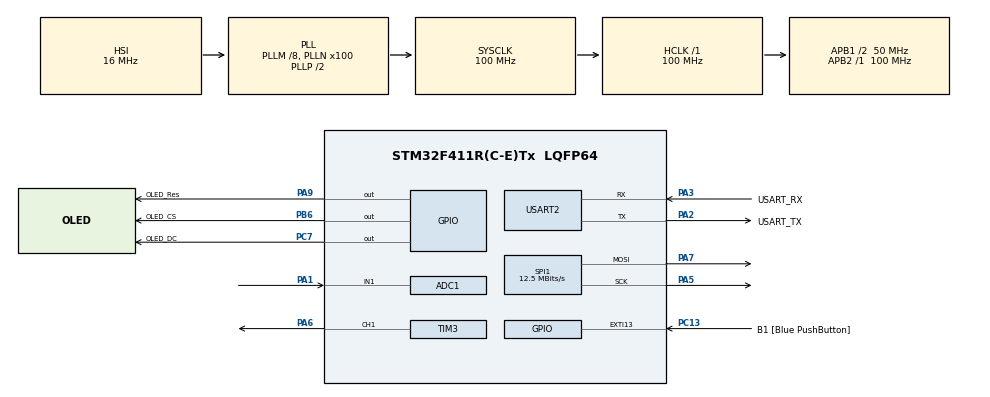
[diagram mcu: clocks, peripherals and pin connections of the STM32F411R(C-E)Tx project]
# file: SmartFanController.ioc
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ADC1.Channel-0\#ChannelRegularConversion=ADC_CHANNEL_1
ADC1.ContinuousConvMode=ENABLE
ADC1.DMAContinuousRequests=ENABLE
ADC1.NbrOfConversionFlag=1
ADC1.Rank-0\#ChannelRegularConversion=1
ADC1.SamplingTime-0\#ChannelRegularConversion=ADC_SAMPLETIME_480CYCLES
ADC1.master=1
Dma.ADC1.0.Direction=DMA_PERIPH_TO_MEMORY
Dma.ADC1.0.FIFOMode=DMA_FIFOMODE_DISABLE
Dma.ADC1.0.Instance=DMA2_Stream0
Dma.ADC1.0.MemDataAlignment=DMA_MDATAALIGN_HALFWORD
Dma.ADC1.0.MemInc=DMA_MINC_ENABLE
Dma.ADC1.0.Mode=DMA_CIRCULAR
Dma.ADC1.0.PeriphDataAlignment=DMA_PDATAALIGN_HALFWORD
Dma.ADC1.0.PeriphInc=DMA_PINC_DISABLE
Dma.ADC1.0.Priority=DMA_PRIORITY_LOW
Dma.Request0=ADC1
Mcu.Family=STM32F4
Mcu.Name=STM32F411R(C-E)Tx
Mcu.Package=LQFP64
NVIC.ADC_IRQn=true\:0\:0\:false\:false\:true\:true\:true\:true
NVIC.DMA2_Stream0_IRQn=true\:0\:0\:false\:false\:true\:false\:true\:true
NVIC.PriorityGroup=NVIC_PRIORITYGROUP_0
NVIC.TIM3_IRQn=true\:0\:0\:false\:false\:true\:true\:true\:true
NVIC.USART2_IRQn=true\:0\:0\:false\:false\:true\:true\:true\:true
PA1.Signal=ADCx_IN1
PA13.GPIO_Label=TMS
PA13.Mode=Serial_Wire
PA13.Signal=SYS_JTMS-SWDIO
PA14.GPIO_Label=TCK
PA14.Mode=Serial_Wire
PA14.Signal=SYS_JTCK-SWCLK
PA2.GPIO_Label=USART_TX
PA2.Mode=Asynchronous
PA2.Signal=USART2_TX
PA3.GPIO_Label=USART_RX
PA3.Mode=Asynchronous
PA3.Signal=USART2_RX
PA5.Mode=TX_Only_Simplex_Unidirect_Master
PA5.Signal=SPI1_SCK
PA6.Signal=S_TIM3_CH1
PA7.Mode=TX_Only_Simplex_Unidirect_Master
PA7.Signal=SPI1_MOSI
PA9.GPIO_Label=OLED_Res
PA9.Signal=GPIO_Output
PB3.GPIO_Label=SWO
PB3.Signal=SYS_JTDO-SWO
PB6.GPIO_Label=OLED_CS
PB6.Signal=GPIO_Output
PC13-ANTI_TAMP.GPIO_Label=B1 [Blue PushButton]
PC13-ANTI_TAMP.GPIO_ModeDefaultEXTI=GPIO_MODE_IT_FALLING
PC13-ANTI_TAMP.Signal=GPXTI13
PC14-OSC32_IN.Mode=LSE-External-Oscillator
PC14-OSC32_IN.Signal=RCC_OSC32_IN
PC15-OSC32_OUT.Mode=LSE-External-Oscillator
PC15-OSC32_OUT.Signal=RCC_OSC32_OUT
PC7.GPIO_Label=OLED_DC
PC7.Signal=GPIO_Output
PH0\ -\ OSC_IN.Mode=HSE-External-Clock-Source
PH0\ -\ OSC_IN.Signal=RCC_OSC_IN
PH1\ -\ OSC_OUT.Mode=HSE-External-Clock-Source
PH1\ -\ OSC_OUT.Signal=RCC_OSC_OUT
ProjectManager.HeapSize=0x200
ProjectManager.StackSize=0x400
ProjectManager.TargetToolchain=STM32CubeIDE
RCC.48MHZClocksFreq_Value=50000000
RCC.AHBFreq_Value=100000000
RCC.APB1CLKDivider=RCC_HCLK_DIV2
RCC.APB1Freq_Value=50000000
RCC.APB1TimFreq_Value=100000000
RCC.APB2Freq_Value=100000000
RCC.APB2TimFreq_Value=100000000
RCC.CortexFreq_Value=100000000
RCC.FLatency-AdvancedSettings=FLASH_LATENCY_3
RCC.HCLKFreq_Value=100000000
RCC.HSE_VALUE=8000000
RCC.HSI_VALUE=16000000
RCC.PLLM=8
RCC.PLLN=100
RCC.SYSCLKFreq_VALUE=100000000
RCC.SYSCLKSource=RCC_SYSCLKSOURCE_PLLCLK
RCC.VCOOutputFreq_Value=200000000
SH.ADCx_IN1.0=ADC1_IN1,IN1
SH.S_TIM3_CH1.0=TIM3_CH1,PWM Generation1 CH1
SPI1.BaudRatePrescaler=SPI_BAUDRATEPRESCALER_8
SPI1.CalculateBaudRate=12.5 MBits/s
SPI1.Direction=SPI_DIRECTION_2LINES
SPI1.Mode=SPI_MODE_MASTER
SPI1.VirtualType=VM_MASTER
TIM3.Channel-PWM\ Generation1\ CH1=TIM_CHANNEL_1
TIM3.Period=1000
TIM3.Prescaler=99
USART2.VirtualMode=VM_ASYNC
VP_TIM3_VS_ClockSourceINT.Mode=Internal
board=NUCLEO-F411RE

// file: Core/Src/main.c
/* USER CODE BEGIN Header */
/**
  ******************************************************************************
  * @file           : main.c
  * @brief          : Main program body
  ******************************************************************************
  * @attention
  *
  * Copyright (c) 2026 STMicroelectronics.
  * All rights reserved.
  *
  * This software is licensed under terms that can be found in the LICENSE file
  * in the root directory of this software component.
  * If no LICENSE file comes with this software, it is provided AS-IS.
  *
  ******************************************************************************
  */
/* USER CODE END Header */
#include "main.h"

/* USER CODE BEGIN Includes */
#include "app.h"
#include "Temp_sensor.h"
#include "UART.h"
#include "ssd1306.h"
/* USER CODE END Includes */

ADC_HandleTypeDef hadc1;
DMA_HandleTypeDef hdma_adc1;

SPI_HandleTypeDef hspi1;

TIM_HandleTypeDef htim3;

UART_HandleTypeDef huart2;

void SystemClock_Config(void);
static void MX_GPIO_Init(void);
static void MX_DMA_Init(void);
static void MX_SPI1_Init(void);
static void MX_TIM3_Init(void);
static void MX_USART2_UART_Init(void);
static void MX_ADC1_Init(void);

int main(void)
{

  /* MCU Configuration--------------------------------------------------------*/

  /* Reset of all peripherals, Initializes the Flash interface and the Systick. */
  HAL_Init();

  /* Configure the system clock */
  SystemClock_Config();

  /* Initialize all configured peripherals */
  MX_GPIO_Init();
  MX_DMA_Init();
  MX_SPI1_Init();
  MX_TIM3_Init();
  MX_USART2_UART_Init();
  MX_ADC1_Init();
  /* USER CODE BEGIN 2 */
  ssd1306_Init();
  HAL_TIM_PWM_Start(&htim3, TIM_CHANNEL_1);
  Temp_init(&hadc1);
  UART_Recive();
  App_Init();
  /* USER CODE END 2 */

  /* Infinite loop */
  /* USER CODE BEGIN WHILE */
  while (1)
  {
	  App_Execution();
	  HAL_Delay(100);
    /* USER CODE END WHILE */

  }
}

void SystemClock_Config(void)
{
  RCC_OscInitTypeDef RCC_OscInitStruct = {0};
  RCC_ClkInitTypeDef RCC_ClkInitStruct = {0};

  /** Configure the main internal regulator output voltage
  */
  __HAL_RCC_PWR_CLK_ENABLE();
  __HAL_PWR_VOLTAGESCALING_CONFIG(PWR_REGULATOR_VOLTAGE_SCALE1);

  /** Initializes the RCC Oscillators according to the specified parameters
  * in the RCC_OscInitTypeDef structure.
  */
  RCC_OscInitStruct.OscillatorType = RCC_OSCILLATORTYPE_HSI;
  RCC_OscInitStruct.HSIState = RCC_HSI_ON;
  RCC_OscInitStruct.HSICalibrationValue = RCC_HSICALIBRATION_DEFAULT;
  RCC_OscInitStruct.PLL.PLLState = RCC_PLL_ON;
  RCC_OscInitStruct.PLL.PLLSource = RCC_PLLSOURCE_HSI;
  RCC_OscInitStruct.PLL.PLLM = 8;
  RCC_OscInitStruct.PLL.PLLN = 100;
  RCC_OscInitStruct.PLL.PLLP = RCC_PLLP_DIV2;
  RCC_OscInitStruct.PLL.PLLQ = 4;
  if (HAL_RCC_OscConfig(&RCC_OscInitStruct) != HAL_OK)
  {
    Error_Handler();
  }

  /** Initializes the CPU, AHB and APB buses clocks
  */
  RCC_ClkInitStruct.ClockType = RCC_CLOCKTYPE_HCLK|RCC_CLOCKTYPE_SYSCLK
                              |RCC_CLOCKTYPE_PCLK1|RCC_CLOCKTYPE_PCLK2;
  RCC_ClkInitStruct.SYSCLKSource = RCC_SYSCLKSOURCE_PLLCLK;
  RCC_ClkInitStruct.AHBCLKDivider = RCC_SYSCLK_DIV1;
  RCC_ClkInitStruct.APB1CLKDivider = RCC_HCLK_DIV2;
  RCC_ClkInitStruct.APB2CLKDivider = RCC_HCLK_DIV1;

  if (HAL_RCC_ClockConfig(&RCC_ClkInitStruct, FLASH_LATENCY_3) != HAL_OK)
  {
    Error_Handler();
  }
}

static void MX_ADC1_Init(void)
{

  ADC_ChannelConfTypeDef sConfig = {0};

  /** Configure the global features of the ADC (Clock, Resolution, Data Alignment and number of conversion)
  */
  hadc1.Instance = ADC1;
  hadc1.Init.ClockPrescaler = ADC_CLOCK_SYNC_PCLK_DIV4;
  hadc1.Init.Resolution = ADC_RESOLUTION_12B;
  hadc1.Init.ScanConvMode = DISABLE;
  hadc1.Init.ContinuousConvMode = ENABLE;
  hadc1.Init.DiscontinuousConvMode = DISABLE;
  hadc1.Init.ExternalTrigConvEdge = ADC_EXTERNALTRIGCONVEDGE_NONE;
  hadc1.Init.ExternalTrigConv = ADC_SOFTWARE_START;
  hadc1.Init.DataAlign = ADC_DATAALIGN_RIGHT;
  hadc1.Init.NbrOfConversion = 1;
  hadc1.Init.DMAContinuousRequests = ENABLE;
  hadc1.Init.EOCSelection = ADC_EOC_SINGLE_CONV;
  if (HAL_ADC_Init(&hadc1) != HAL_OK)
  {
    Error_Handler();
  }

  /** Configure for the selected ADC regular channel its corresponding rank in the sequencer and its sample time.
  */
  sConfig.Channel = ADC_CHANNEL_1;
  sConfig.Rank = 1;
  sConfig.SamplingTime = ADC_SAMPLETIME_480CYCLES;
  if (HAL_ADC_ConfigChannel(&hadc1, &sConfig) != HAL_OK)
  {
    Error_Handler();
  }

}

static void MX_SPI1_Init(void)
{

  /* SPI1 parameter configuration*/
  hspi1.Instance = SPI1;
  hspi1.Init.Mode = SPI_MODE_MASTER;
  hspi1.Init.Direction = SPI_DIRECTION_2LINES;
  hspi1.Init.DataSize = SPI_DATASIZE_8BIT;
  hspi1.Init.CLKPolarity = SPI_POLARITY_LOW;
  hspi1.Init.CLKPhase = SPI_PHASE_1EDGE;
  hspi1.Init.NSS = SPI_NSS_SOFT;
  hspi1.Init.BaudRatePrescaler = SPI_BAUDRATEPRESCALER_8;
  hspi1.Init.FirstBit = SPI_FIRSTBIT_MSB;
  hspi1.Init.TIMode = SPI_TIMODE_DISABLE;
  hspi1.Init.CRCCalculation = SPI_CRCCALCULATION_DISABLE;
  hspi1.Init.CRCPolynomial = 10;
  if (HAL_SPI_Init(&hspi1) != HAL_OK)
  {
    Error_Handler();
  }

}

static void MX_TIM3_Init(void)
{

  TIM_ClockConfigTypeDef sClockSourceConfig = {0};
  TIM_MasterConfigTypeDef sMasterConfig = {0};
  TIM_OC_InitTypeDef sConfigOC = {0};

  htim3.Instance = TIM3;
  htim3.Init.Prescaler = 99;
  htim3.Init.CounterMode = TIM_COUNTERMODE_UP;
  htim3.Init.Period = 1000;
  htim3.Init.ClockDivision = TIM_CLOCKDIVISION_DIV1;
  htim3.Init.AutoReloadPreload = TIM_AUTORELOAD_PRELOAD_DISABLE;
  if (HAL_TIM_Base_Init(&htim3) != HAL_OK)
  {
    Error_Handler();
  }
  sClockSourceConfig.ClockSource = TIM_CLOCKSOURCE_INTERNAL;
  if (HAL_TIM_ConfigClockSource(&htim3, &sClockSourceConfig) != HAL_OK)
  {
    Error_Handler();
  }
  if (HAL_TIM_PWM_Init(&htim3) != HAL_OK)
  {
    Error_Handler();
  }
  sMasterConfig.MasterOutputTrigger = TIM_TRGO_RESET;
  sMasterConfig.MasterSlaveMode = TIM_MASTERSLAVEMODE_DISABLE;
  if (HAL_TIMEx_MasterConfigSynchronization(&htim3, &sMasterConfig) != HAL_OK)
  {
    Error_Handler();
  }
  sConfigOC.OCMode = TIM_OCMODE_PWM1;
  sConfigOC.Pulse = 0;
  sConfigOC.OCPolarity = TIM_OCPOLARITY_HIGH;
  sConfigOC.OCFastMode = TIM_OCFAST_DISABLE;
  if (HAL_TIM_PWM_ConfigChannel(&htim3, &sConfigOC, TIM_CHANNEL_1) != HAL_OK)
  {
    Error_Handler();
  }
  HAL_TIM_MspPostInit(&htim3);

}

static void MX_USART2_UART_Init(void)
{

  huart2.Instance = USART2;
  huart2.Init.BaudRate = 115200;
  huart2.Init.WordLength = UART_WORDLENGTH_8B;
  huart2.Init.StopBits = UART_STOPBITS_1;
  huart2.Init.Parity = UART_PARITY_NONE;
  huart2.Init.Mode = UART_MODE_TX_RX;
  huart2.Init.HwFlowCtl = UART_HWCONTROL_NONE;
  huart2.Init.OverSampling = UART_OVERSAMPLING_16;
  if (HAL_UART_Init(&huart2) != HAL_OK)
  {
    Error_Handler();
  }

}

static void MX_DMA_Init(void)
{

  /* DMA controller clock enable */
  __HAL_RCC_DMA2_CLK_ENABLE();

  /* DMA interrupt init */
  /* DMA2_Stream0_IRQn interrupt configuration */
  HAL_NVIC_SetPriority(DMA2_Stream0_IRQn, 0, 0);
  HAL_NVIC_EnableIRQ(DMA2_Stream0_IRQn);

}

static void MX_GPIO_Init(void)
{
  GPIO_InitTypeDef GPIO_InitStruct = {0};

  /* GPIO Ports Clock Enable */
  __HAL_RCC_GPIOC_CLK_ENABLE();
  __HAL_RCC_GPIOH_CLK_ENABLE();
  __HAL_RCC_GPIOA_CLK_ENABLE();
  __HAL_RCC_GPIOB_CLK_ENABLE();

  /*Configure GPIO pin Output Level */
  HAL_GPIO_WritePin(OLED_DC_GPIO_Port, OLED_DC_Pin, GPIO_PIN_RESET);

  /*Configure GPIO pin Output Level */
  HAL_GPIO_WritePin(OLED_Res_GPIO_Port, OLED_Res_Pin, GPIO_PIN_RESET);

  /*Configure GPIO pin Output Level */
  HAL_GPIO_WritePin(OLED_CS_GPIO_Port, OLED_CS_Pin, GPIO_PIN_RESET);

  /*Configure GPIO pin : B1_Pin */
  GPIO_InitStruct.Pin = B1_Pin;
  GPIO_InitStruct.Mode = GPIO_MODE_IT_FALLING;
  GPIO_InitStruct.Pull = GPIO_NOPULL;
  HAL_GPIO_Init(B1_GPIO_Port, &GPIO_InitStruct);

  /*Configure GPIO pin : OLED_DC_Pin */
  GPIO_InitStruct.Pin = OLED_DC_Pin;
  GPIO_InitStruct.Mode = GPIO_MODE_OUTPUT_PP;
  GPIO_InitStruct.Pull = GPIO_NOPULL;
  GPIO_InitStruct.Speed = GPIO_SPEED_FREQ_LOW;
  HAL_GPIO_Init(OLED_DC_GPIO_Port, &GPIO_InitStruct);

  /*Configure GPIO pin : OLED_Res_Pin */
  GPIO_InitStruct.Pin = OLED_Res_Pin;
  GPIO_InitStruct.Mode = GPIO_MODE_OUTPUT_PP;
  GPIO_InitStruct.Pull = GPIO_NOPULL;
  GPIO_InitStruct.Speed = GPIO_SPEED_FREQ_LOW;
  HAL_GPIO_Init(OLED_Res_GPIO_Port, &GPIO_InitStruct);

  /*Configure GPIO pin : OLED_CS_Pin */
  GPIO_InitStruct.Pin = OLED_CS_Pin;
  GPIO_InitStruct.Mode = GPIO_MODE_OUTPUT_PP;
  GPIO_InitStruct.Pull = GPIO_NOPULL;
  GPIO_InitStruct.Speed = GPIO_SPEED_FREQ_LOW;
  HAL_GPIO_Init(OLED_CS_GPIO_Port, &GPIO_InitStruct);

}

void Error_Handler(void)
{
  __disable_irq();
  while (1)
  {
  }
}
